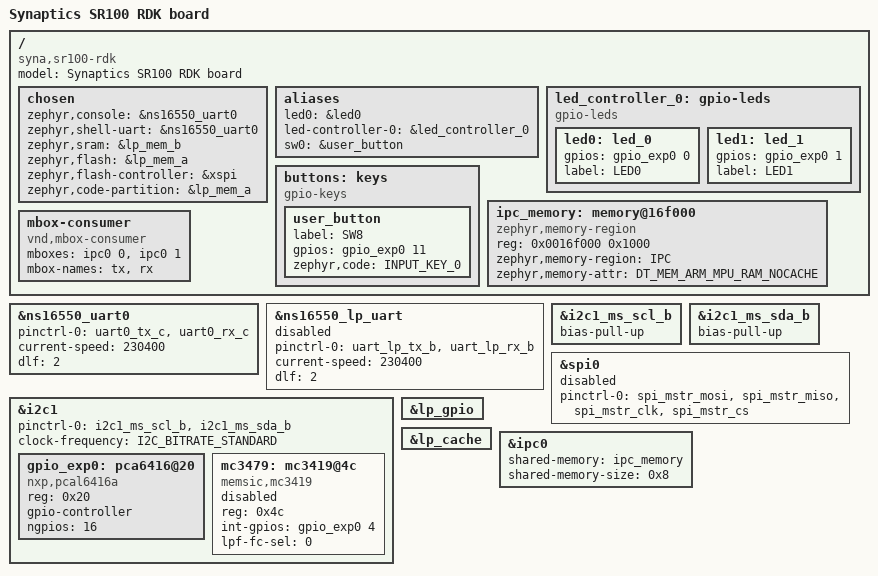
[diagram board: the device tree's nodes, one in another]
/*
 * Copyright (c) 2025 Synaptics Incorporated
 *
 * SPDX-License-Identifier: Apache-2.0
 */

/dts-v1/;
#include <syna/astra_sr/sr100_m4.dtsi>
#include <syna/astra_sr/sr100_pinctrl.dtsi>
#include <zephyr/dt-bindings/gpio/gpio.h>
#include <zephyr/dt-bindings/input/input-event-codes.h>

/ {
	model = "Synaptics SR100 RDK board";
	compatible = "syna,sr100-rdk";

	chosen {
		zephyr,console = &ns16550_uart0;
		zephyr,shell-uart = &ns16550_uart0;
		zephyr,sram = &lp_mem_b;
		zephyr,flash = &lp_mem_a;
		zephyr,flash-controller = &xspi;
		zephyr,code-partition = &lp_mem_a;
	};

	aliases {
		led0 = &led0;
		led-controller-0 = &led_controller_0;
		sw0 = &user_button;
	};

	led_controller_0: gpio-leds {
		compatible = "gpio-leds";

		led0: led_0 {
			gpios = <&gpio_exp0 0 GPIO_ACTIVE_HIGH>;
			label = "LED0";
		};

		led1: led_1 {
			gpios = <&gpio_exp0 1 GPIO_ACTIVE_HIGH>;
			label = "LED1";
		};
	};

	buttons: keys {
		compatible = "gpio-keys";

		user_button: user_button {
			label = "SW8";
			gpios = <&gpio_exp0 11 GPIO_ACTIVE_HIGH>;
			zephyr,code = <INPUT_KEY_0>;
		};
	};

	ipc_memory: memory@16f000 { /* End of LP_MEMB area */
		compatible = "zephyr,memory-region";
		reg = <0x0016f000 0x1000>;
		#address-cells = <1>;
		#size-cells = <1>;
		ranges = <0x0 0x0016f000 0x1000>;
		zephyr,memory-region = "IPC";
		zephyr,memory-attr = <DT_MEM_ARM_MPU_RAM_NOCACHE>;
	};

	mbox-consumer {
		compatible = "vnd,mbox-consumer";
		mboxes = <&ipc0 0>, <&ipc0 1>;
		mbox-names = "tx", "rx";
	};
};

&ns16550_uart0 {
	pinctrl-0 = <&uart0_tx_c &uart0_rx_c>;
	pinctrl-names = "default";
	current-speed = <230400>;
	dlf = <2>;
	status = "okay";
};

&ns16550_lp_uart {
	pinctrl-0 = <&uart_lp_tx_b &uart_lp_rx_b>;
	pinctrl-names = "default";
	current-speed = <230400>;
	dlf = <2>;
	status = "disabled";
};

&i2c1_ms_scl_b {
	bias-pull-up;
};

&i2c1_ms_sda_b {
	bias-pull-up;
};

&i2c1 {
	status = "okay";
	pinctrl-0 = <&i2c1_ms_scl_b &i2c1_ms_sda_b>;
	pinctrl-names = "default";
	clock-frequency = <I2C_BITRATE_STANDARD>;

	gpio_exp0: pca6416@20 {
		compatible = "nxp,pcal6416a";
		reg = <0x20>;
		gpio-controller;
		#gpio-cells = <2>;
		ngpios = <16>;
	};

	mc3479: mc3419@4c {
		compatible = "memsic,mc3419";
		status = "disabled";
		reg = <0x4c>;
		int-gpios = <&gpio_exp0 4 0>;
		lpf-fc-sel = <0>;
	};
};

&spi0 {
	/* Note that the default pinmux configuration for this board uses GP23/GP24
	 * for UART1_TX/UART1_RX respectively, which conflicts with the
	 * spi_mstr_mosi/spi_mstr_miso muxes.
	 */
	pinctrl-0 = <&spi_mstr_mosi &spi_mstr_miso &spi_mstr_clk &spi_mstr_cs>;
	pinctrl-names = "default";
	status = "disabled";
};

&lp_gpio {
	status = "okay";
};

&lp_cache {
	status = "okay";
};

&ipc0 {
	status = "okay";
	shared-memory = <&ipc_memory>;
	shared-memory-size = <0x8>; /* only valid size for mbox_data sample */
	#mbox-cells = <1>;
};
